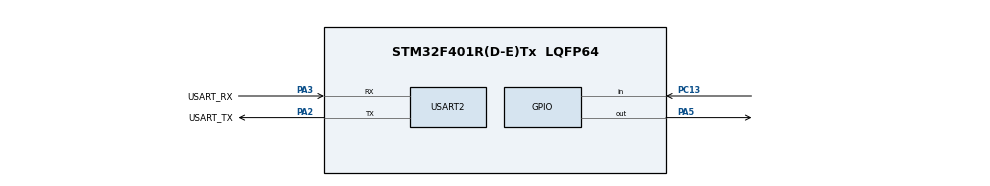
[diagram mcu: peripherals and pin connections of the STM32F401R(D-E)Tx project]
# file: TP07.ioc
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Mcu.Family=STM32F4
PA2.GPIO_PuPd=GPIO_NOPULL
RCC.CortexFreq_Value=10500000
Dma.USART2_TX.1.MemInc=DMA_MINC_ENABLE
PA14.GPIO_Label=TCK
PA3.GPIO_PuPd=GPIO_NOPULL
PA2.GPIO_Speed=GPIO_SPEED_FREQ_LOW
Dma.USART2_RX.0.MemBurst=DMA_MBURST_SINGLE
PA3.GPIO_Speed=GPIO_SPEED_FREQ_LOW
RCC.SYSCLKSource=RCC_SYSCLKSOURCE_PLLCLK
ProjectManager.StackSize=0x400
PH0\ -\ OSC_IN.Signal=RCC_OSC_IN
Dma.USART2_RX.0.Priority=DMA_PRIORITY_LOW
Dma.USART2_TX.1.PeriphBurst=DMA_PBURST_SINGLE
Dma.USART2_RX.0.PeriphDataAlignment=DMA_PDATAALIGN_BYTE
RCC.HCLKFreq_Value=84000000
RCC.APB2TimFreq_Value=84000000
Dma.USART2_TX.1.Mode=DMA_NORMAL
RCC.AHBFreq_Value=84000000
Dma.USART2_RX.0.PeriphBurst=DMA_PBURST_SINGLE
RCC.HSE_VALUE=8000000
PC13-ANTI_TAMP.Signal=GPIO_Input
Dma.USART2_RX.0.MemDataAlignment=DMA_MDATAALIGN_BYTE
PC14-OSC32_IN.Mode=LSE-External-Oscillator
PA14.Mode=Serial_Wire
Dma.USART2_TX.1.Instance=DMA1_Stream6
Dma.USART2_RX.0.Instance=DMA1_Stream5
Dma.USART2_TX.1.MemBurst=DMA_MBURST_SINGLE
Mcu.Package=LQFP64
NVIC.TimeBase=TIM1_BRK_TIM9_IRQn
Dma.USART2_RX.0.PeriphInc=DMA_PINC_DISABLE
Dma.USART2_TX.1.FIFOThreshold=DMA_FIFO_THRESHOLD_FULL
USART2.VirtualMode=VM_ASYNC
Dma.USART2_RX.0.FIFOMode=DMA_FIFOMODE_ENABLE
PA2.GPIO_Label=USART_TX
NVIC.TimeBaseIP=TIM9
Dma.Request1=USART2_TX
RCC.APB1TimFreq_Value=84000000
NVIC.DMA1_Stream6_IRQn=true\:10\:0\:true\:false\:true\:false\:true
Dma.Request0=USART2_RX
PA3.Signal=USART2_RX
PA2.GPIO_Mode=GPIO_MODE_AF_PP
PB3.GPIO_Label=SWO
RCC.PLLSourceVirtual=RCC_PLLSOURCE_HSE
PC15-OSC32_OUT.Mode=LSE-External-Oscillator
Dma.USART2_TX.1.Priority=DMA_PRIORITY_LOW
Dma.USART2_TX.1.FIFOMode=DMA_FIFOMODE_ENABLE
PH1\ -\ OSC_OUT.Mode=HSE-External-Clock-Source
Dma.USART2_RX.0.Direction=DMA_PERIPH_TO_MEMORY
RCC.APB1CLKDivider=RCC_HCLK_DIV2
PC14-OSC32_IN.Signal=RCC_OSC32_IN
Dma.USART2_TX.1.PeriphDataAlignment=DMA_PDATAALIGN_BYTE
NVIC.USART2_IRQn=true\:10\:0\:true\:false\:true\:true\:true
Dma.USART2_RX.0.Mode=DMA_NORMAL
Dma.USART2_RX.0.FIFOThreshold=DMA_FIFO_THRESHOLD_FULL
VP_SYS_VS_tim9.Mode=TIM9
PA13.Signal=SYS_JTMS-SWDIO
PA3.Mode=Asynchronous
PH0\ -\ OSC_IN.Mode=HSE-External-Clock-Source
ProjectManager.TargetToolchain=STM32CubeIDE
NVIC.DMA1_Stream5_IRQn=true\:10\:0\:true\:false\:true\:false\:true
PA3.GPIO_Mode=GPIO_MODE_AF_PP
PC15-OSC32_OUT.Signal=RCC_OSC32_OUT
PA5.Signal=GPIO_Output
PH1\ -\ OSC_OUT.Signal=RCC_OSC_OUT
Dma.USART2_TX.1.PeriphInc=DMA_PINC_DISABLE
board=NUCLEO-F401RE
RCC.VCOOutputFreq_Value=168000000
Dma.USART2_TX.1.Direction=DMA_MEMORY_TO_PERIPH
RCC.APB2Freq_Value=84000000
PA13.Mode=Serial_Wire
Mcu.Name=STM32F401R(D-E)Tx
Dma.USART2_RX.0.MemInc=DMA_MINC_ENABLE
NVIC.TIM1_BRK_TIM9_IRQn=true\:14\:0\:true\:false\:true\:false\:true
PA13.GPIO_Label=TMS
PA2.Signal=USART2_TX
RCC.48MHZClocksFreq_Value=24000000
PB3.Signal=SYS_JTDO-SWO
RCC.SYSCLKFreq_VALUE=84000000
PA14.Signal=SYS_JTCK-SWCLK
ProjectManager.HeapSize=0x200
RCC.HSI_VALUE=16000000
RCC.PLLQ=7
NVIC.PriorityGroup=NVIC_PRIORITYGROUP_4
RCC.PLLM=4
RCC.PLLN=84
PA2.Mode=Asynchronous
RCC.Cortex_Div=SYSTICK_CLKSOURCE_HCLK_DIV8
Dma.USART2_TX.1.MemDataAlignment=DMA_MDATAALIGN_BYTE
RCC.APB1Freq_Value=42000000
PA3.GPIO_Label=USART_RX

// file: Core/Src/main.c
/* USER CODE BEGIN Header */
/**
  ******************************************************************************
  * @file           : main.c
  * @brief          : Main program body
  ******************************************************************************
  * @attention
  *
  * <h2><center>&copy; Copyright (c) 2022 STMicroelectronics.
  * All rights reserved.</center></h2>
  *
  * This software component is licensed by ST under BSD 3-Clause license,
  * the "License"; You may not use this file except in compliance with the
  * License. You may obtain a copy of the License at:
  *                        opensource.org/licenses/BSD-3-Clause
  *
  ******************************************************************************
  */
/* USER CODE END Header */
#include "main.h"
#include "dma.h"
#include "usart.h"
#include "gpio.h"

/* USER CODE BEGIN Includes */

#include "app_tasks.h"

/* USER CODE END Includes */

void SystemClock_Config(void);

int main(void)
{

  /* MCU Configuration--------------------------------------------------------*/

  /* Reset of all peripherals, Initializes the Flash interface and the Systick. */
  HAL_Init();

  /* Configure the system clock */
  SystemClock_Config();

  /* Initialize all configured peripherals */
  MX_GPIO_Init();
  MX_DMA_Init();
  MX_USART2_UART_Init();
  /* USER CODE BEGIN 2 */

  start_application();

  /* USER CODE END 2 */

  /* Infinite loop */
  while (1)
  {

  }
}

void SystemClock_Config(void)
{
  LL_FLASH_SetLatency(LL_FLASH_LATENCY_2);
  while(LL_FLASH_GetLatency()!= LL_FLASH_LATENCY_2)
  {
  }
  LL_PWR_SetRegulVoltageScaling(LL_PWR_REGU_VOLTAGE_SCALE2);
  LL_RCC_HSE_EnableBypass();
  LL_RCC_HSE_Enable();

   /* Wait till HSE is ready */
  while(LL_RCC_HSE_IsReady() != 1)
  {

  }
  LL_RCC_PLL_ConfigDomain_SYS(LL_RCC_PLLSOURCE_HSE, LL_RCC_PLLM_DIV_4, 84, LL_RCC_PLLP_DIV_2);
  LL_RCC_PLL_Enable();

   /* Wait till PLL is ready */
  while(LL_RCC_PLL_IsReady() != 1)
  {

  }
  LL_RCC_SetAHBPrescaler(LL_RCC_SYSCLK_DIV_1);
  LL_RCC_SetAPB1Prescaler(LL_RCC_APB1_DIV_2);
  LL_RCC_SetAPB2Prescaler(LL_RCC_APB2_DIV_1);
  LL_RCC_SetSysClkSource(LL_RCC_SYS_CLKSOURCE_PLL);

   /* Wait till System clock is ready */
  while(LL_RCC_GetSysClkSource() != LL_RCC_SYS_CLKSOURCE_STATUS_PLL)
  {

  }
  LL_SetSystemCoreClock(84000000);

   /* Update the time base */
  if (HAL_InitTick (TICK_INT_PRIORITY) != HAL_OK)
  {
    Error_Handler();
  }
  LL_RCC_SetTIMPrescaler(LL_RCC_TIM_PRESCALER_TWICE);
}

 /**
  * @brief  Period elapsed callback in non blocking mode
  * @note   This function is called  when TIM9 interrupt took place, inside
  * HAL_TIM_IRQHandler(). It makes a direct call to HAL_IncTick() to increment
  * a global variable "uwTick" used as application time base.
  * @param  htim : TIM handle
  * @retval None
  */
void HAL_TIM_PeriodElapsedCallback(TIM_HandleTypeDef *htim)
{
  if (htim->Instance == TIM9) {
    HAL_IncTick();
  }
}

void Error_Handler(void)
{
  __disable_irq();
  while (1)
  {
  }
}

/************************ (C) COPYRIGHT STMicroelectronics *****END OF FILE****/
